# CM33 register map
Registers are 32-bit, read-write, reset 0x0 unless marked. A register's access mark holds for its fields unless they carry their own. Offsets are from the block's base; [hi:lo] are bit positions; {n}, {i} and the like mark numbered series.

## SCB — System Control Block
Base 0xE000ED00
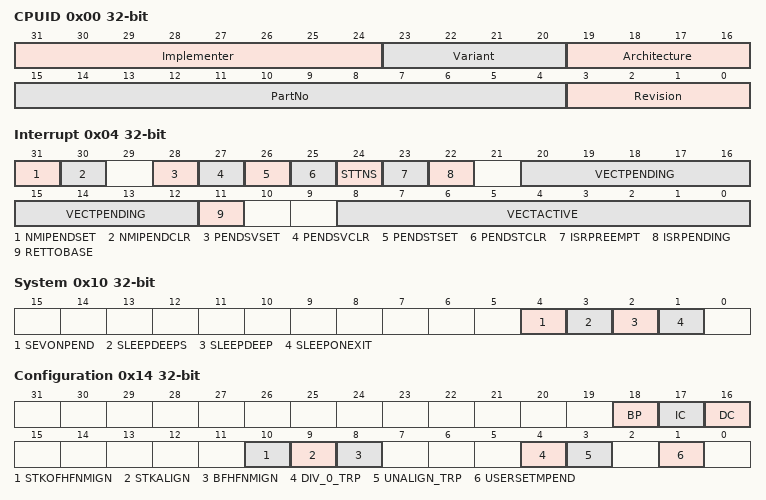
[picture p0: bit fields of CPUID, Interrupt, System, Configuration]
0x00 CPUID Base Register ro — Provides identification information for the PE, including an implementer code for the device and a device ID number
  [31:24] Implementer — Implementer code. This field must hold an implementer code that has been assigned by ARM
  [23:20] Variant — Variant number. IMPLEMENTATION DEFINED variant number
  [19:16] Architecture — Architecture version. Defines the Architecture implemented by the PE
  [15:4] PartNo — Part number. IMPLEMENTATION DEFINED primary part number for the device
  [3:0] Revision — Revision number. IMPLEMENTATION DEFINED revision number for the device
0x04 Interrupt Control and State Register — Controls and provides status information for NMI, PendSV, SysTick and interrupts
  [31] NMIPENDSET write-1-sets — Pend NMI set. Allows the NMI exception to be set as pending
    0=No effect; 1=set pending (Sets the NMI exception pending)
  [30] NMIPENDCLR write-1-sets — Pend NMI clear. Allows the NMI exception pend state to be cleared
    0=No effect; 1=Clear pending status
  [28] PENDSVSET write-1-sets — Pend PendSV set. Indicates whether the PendSV for the selected Security state exception is pending
    0=PendSV exception not pending; 1=set pending (PendSV exception pending)
  [27] PENDSVCLR write-1-sets — Pend PendSV clear
    0=No effect; 1=Clear pending status
  [26] PENDSTSET write-1-sets — Pend SysTick set. Indicates whether the SysTick for the selected Security state exception is pending
    0=cleared (SysTick exception not pending); 1=set_pending (SysTick exception pending)
  [25] PENDSTCLR write-1-sets — Pend SysTick clear
    0=No effect; 1=Clear pending status
  [24] STTNS — SysTick Targets Non-secure
    0=SysTick is Secure; 1=SysTick is Non-secure
  [23] ISRPREEMPT — Interrupt preempt
    0=Will not service; 1=Will service a pending exception
  [22] ISRPENDING — Interrupt pending. Indicates whether an external interrupt, generated by the NVIC, is pending
    0=No external interrupt pending; 1=External interrupt pending
  [20:12] VECTPENDING — Vector pending. The exception number of the highest priority pending and enabled interrupt
  [11] RETTOBASE — Return to base. In Handler mode, indicates whether there is more than one active exception
    0=There is more than one active exception; 1=There is only one active exception
  [8:0] VECTACTIVE — Vector active. The exception number of the current executing exception
0x08 Vector Table Offset Register — Holds the vector table address for the selected Security state
  [31:7] TBLOFF — Bits[31:7] of the vector table address
0x0C Application Interrupt and Reset Control Register — Sets or returns interrupt control and reset configuration
  [31:16] VECTKEY wo range 0x05FA..0x05FA — Vector key. Writes to the AIRCR must be accompanied by a write of the value 0x05FA to this field
    0=Do not request a reset; 0x5FA=Request reset
  [31:16] VECTKEYSTAT ro — Vector key status. Returns the bitwise inverse of the value required to be written to VECTKEY
  [15] ENDIANNESS — Data endianness. Indicates how the PE interprets the memory system data endianness
    0=Little-endian; 1=Big-endian
  [14] PRIS — Prioritize Secure exceptions
    0=Priority ranges of Secure and Non-secure exceptions are identical; 1=Non-secure exceptions are de-prioritized
  [13] BFHFNMINS — BusFault, HardFault, and NMI Non-secure enable
    0=BusFault, HardFault, and NMI are Secure; 1=BusFault and NMI are Non-secure and exceptions can target Non-secure HardFault
  [10:8] PRIGROUP — Priority grouping
    0=Group priority [7:1], subpriority [0]; {v}=Group priority [7:{v+1}], subpriority [{v}:0] (v=1..5)
  [3] SYSRESETREQS — System reset request Secure only
    0=SYSRESETREQ functionality is available to both Security states; 1=SYSRESETREQ functionality is only available to Secure state
  [2] SYSRESETREQ — System reset request. This bit allows software or a debugger to request a system reset
    0=Do not request a system reset; 1=Request reset (Request a system reset)
  [1] VECTCLRACTIVE — Clear active state
    0=Do not clear active state; 1=Clear active state
0x10 System Control Register — Sets or returns system control data
  [4] SEVONPEND — Send event on pend
    0=Transitions from inactive to pending are not wakeup events; 1=Transitions from inactive to pending are wakeup events
  [3] SLEEPDEEPS — Sleep deep secure
    0=The SLEEPDEEP bit accessible from both Security states; 1=The SLEEPDEEP bit behaves as RAZ/WI when accessed from the Non-secure state
  [2] SLEEPDEEP — Sleep deep. Provides a qualifying hint indicating that waking from sleep might take longer
    0=Selected sleep state is not deep sleep; 1=Selected sleep state is deep sleep
  [1] SLEEPONEXIT
    0=Enter sleep state disabled; 1=Enter sleep state permitted
0x14 Configuration and Control Register — Sets or returns configuration and control data
  [18] BP — Branch prediction enable. Enables program flow prediction for the selected Security state
    0=Program flow prediction disabled for the selected Security state; 1=Program flow prediction enabled for the selected Security state
  [17] IC — Instruction cache enable. This is a global enable bit for instruction caches in the selected Security state.
    0=Instruction caches disabled for the selected Security state; 1=Instruction caches enabled for the selected Security state
  [16] DC — Data cache enable. Enables data caching of all data accesses to Normal memory for the selected security state
    0=Data caching disabled for the selected Security state; 1=Data caching enabled for the selected Security state
  [10] STKOFHFNMIGN — Stack overflow in HardFault and NMI ignore. Controls the effect of a stack limit violation while executing at a requested priority less than 0 for the Security state with which the stack limit register is associated
    0=Stack limit faults not ignored; 1=Stack limit faults at requested priorities of less than 0 ignored
  [9] STKALIGN — Stack alignment. Controls whether the stack is automatically aligned to 8-byte boundary on exception entry
    0=Stack aligned to 4-byte boundary on exception entry; 1=Stack automatically aligned to 8-byte boundary on exception entry
  [8] BFHFNMIGN — BusFault in HardFault or NMI ignore. Determines the effect of precise BusFaults on handlers running at a requested priority less than 0
    0=Precise BusFaults not ignored; 1=Precise BusFaults at requested priorities of less than 0 ignored
  [4] DIV_0_TRP — Divide by zero trap. Controls the generation of a DIVBYZERO UsageFault when attempting to perform integer division by zero
    0=DIVBYZERO UsageFault generation disabled; 1=DIVBYZERO UsageFault generation enabled
  [3] UNALIGN_TRP — Unaligned trap. Controls the trapping of unaligned word or halfword accesses
    0=Unaligned accesses permitted from LDR, LDRH, STR, and STRH; 1=Any unaligned transaction generates an UNALIGNED UsageFault
  [1] USERSETMPEND — User set main pending. Determines whether unprivileged accesses are permitted to pend interrupts via the STIR
    0=Unprivileged accesses to the STIR generate a fault; 1=Unprivileged accesses to the STIR are permitted
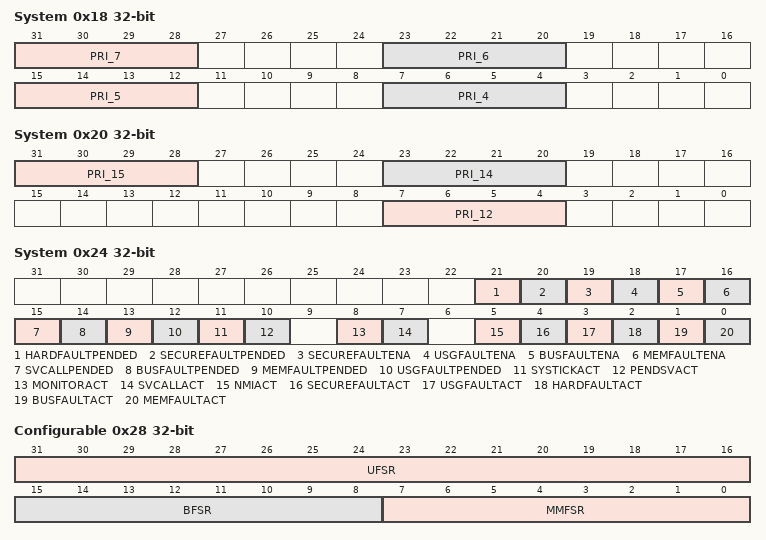
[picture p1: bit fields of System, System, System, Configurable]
0x18 System Handler Priority Register 1 — Sets or returns priority for system handlers 4 - 7
  [31:28] PRI_7 — Priority 7. Priority of system handler 7, SecureFault
  [23:20] PRI_6 — Priority 6. Priority of system handler 6, UsageFault
  [15:12] PRI_5 — Priority 5. Priority of system handler 5, BusFault
  [7:4] PRI_4 — Priority 4. Priority of system handler 4, MemManage
0x1C System Handler Priority Register 2 — Sets or returns priority for system handlers 8 - 11
  [31:28] PRI_11 — Priority 11. Priority of system handler 11, SVCall
0x20 System Handler Priority Register 3 — Sets or returns priority for system handlers 12 - 15
  [31:28] PRI_15 — Priority 15. Priority of system handler 15, SysTick
  [23:20] PRI_14 — Priority 14. Priority of system handler 14, PendSV
  [7:4] PRI_12 — Priority 12. Priority of system handler 12, DebugMonitor
0x24 System Handler Control and State Register — Provides access to the active and pending status of system exceptions
  [21] HARDFAULTPENDED — HardFault exception pended state
    0=HardFault exception not pending for the selected Security state; 1=HardFault exception pending for the selected Security state
  [20] SECUREFAULTPENDED — SecureFault exception pended state
    0=SecureFault exception not pending; 1=SecureFault exception pending
  [19] SECUREFAULTENA — SecureFault exception enable
    0=SecureFault exception disabled; 1=SecureFault exception enabled
  [18] USGFAULTENA — UsageFault exception enable
    0=UsageFault exception disabled for the selected Security state; 1=UsageFault exception enabled for the selected Security state
  [17] BUSFAULTENA — BusFault exception enable. The value of this bit defines whether the BusFault exception is enabled
    0=BusFault exception disabled; 1=BusFault exception enabled
  [16] MEMFAULTENA — MemManage exception enable
    0=MemManage exception disabled for the selected Security state; 1=MemManage exception enabled for the selected Security state
  [15] SVCALLPENDED — SVCall exception pended state
    0=SVCall exception not pending for the selected Security state; 1=SVCall exception pending for the selected Security state
  [14] BUSFAULTPENDED — BusFault exception pended state
    0=BusFault exception not pending; 1=BusFault exception pending
  [13] MEMFAULTPENDED — MemManage exception pended state
    0=MemManage exception not pending for the selected Security state; 1=MemManage exception pending for the selected Security state
  [12] USGFAULTPENDED — UsageFault exception pended state
    0=UsageFault exception not pending for the selected Security state; 1=UsageFault exception pending for the selected Security state
  [11] SYSTICKACT — SysTick exception active state
    0=SysTick exception not active for the selected Security state; 1=SysTick exception active for the selected Security state
  [10] PENDSVACT — PendSV exception active state
    0=PendSV exception not active for the selected Security state; 1=PendSV exception active for the selected Security state
  [8] MONITORACT — DebugMonitor exception active state
    0=DebugMonitor exception not active; 1=DebugMonitor exception active
  [7] SVCALLACT — SVCall exception active state
    0=SVCall exception not active for the selected Security state; 1=SVCall exception active for the selected Security state
  [5] NMIACT — NMI exception active state
    0=NMI exception not active; 1=NMI exception active
  [4] SECUREFAULTACT — SecureFault exception active state
    0=SecureFault exception not active; 1=SecureFault exception active
  [3] USGFAULTACT — UsageFault exception active state for the selected Security state
    0=UsageFault exception not active for the selected Security state; 1=UsageFault exception active for the selected Security state
  [2] HARDFAULTACT — HardFault exception active state
    0=HardFault exception not active for the selected Security state; 1=HardFault exception active for the selected Security state
  [1] BUSFAULTACT — BusFault exception active state
    0=BusFault exception not active; 1=BusFault exception active
  [0] MEMFAULTACT — MemManage exception active state for the selected Security state
    0=MemManage exception not active for the selected Security state; 1=MemManage exception active for the selected Security state
0x28 Configurable Fault Status Register — Contains the three Configurable Fault Status Registers
  [31:16] UFSR — UsageFault Status Register. Provides information on UsageFault exceptions
  [15:8] BFSR — BusFault Status Register. Provides information on BusFault exceptions
  [7:0] MMFSR — MemManage Fault Status Register. Provides information on MemManage exceptions
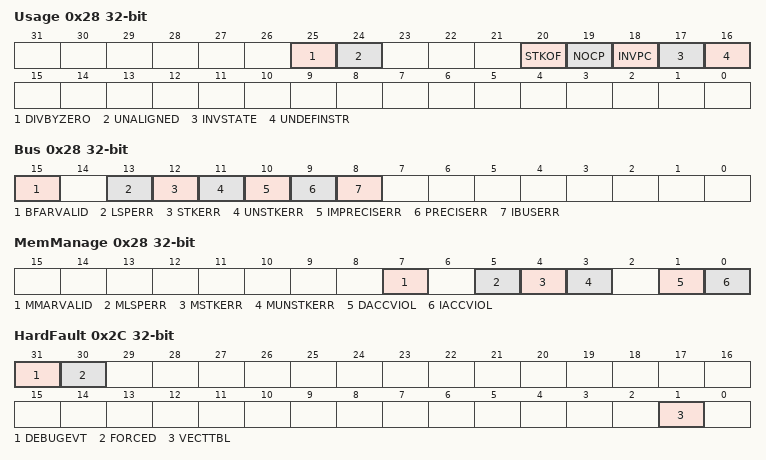
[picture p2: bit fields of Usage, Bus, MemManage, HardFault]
0x28 Usage Fault Status Register — Provides information on UsageFault exceptions
  [all] fields
    0=Error has not occurred; 1=Error has occurred
  [25] DIVBYZERO — Divide by zero flag. Indicates whether an integer division by zero error has occurred
  [24] UNALIGNED — Unaligned access flag. Indicates whether an unaligned access error has occurred
  [20] STKOF — Stack overflow flag. Indicates whether a stack overflow error has occurred
  [19] NOCP — No coprocessor flag. Indicates whether a coprocessor disabled or not present error has occurred
  [18] INVPC — Invalid PC flag. Indicates whether an integrity check error has occurred
  [17] INVSTATE — Invalid state flag. Indicates whether an EPSR.T or EPSR.IT validity error has occurred
  [16] UNDEFINSTR — Undefined instruction flag. Indicates whether an undefined instruction error has occurred
0x28 Bus Fault Status Register — Provides information on BusFault exceptions
  [15] BFARVALID — BFAR valid. Indicates validity of the contents of the BFAR register
    0=BFAR content not valid; 1=BFAR content valid
  [13] LSPERR — Lazy state preservation error. Records whether a BusFault occurred during FP lazy state preservation
    0=No BusFault occurred during FP lazy state preservation; 1=BusFault occurred during FP lazy state preservation
  [12] STKERR — Stack error. Records whether a derived BusFault occurred during exception entry stacking
    0=No derived BusFault occurred; 1=Derived BusFault occurred during exception entry
  [11] UNSTKERR — Unstack error. Records whether a derived BusFault occurred during exception return unstacking
    0=No derived BusFault occurred; 1=Derived BusFault occurred during exception return
  [10] IMPRECISERR — Imprecise error. Records whether an imprecise data access error has occurred
    0=No imprecise data access error has occurred; 1=Imprecise data access error has occurred
  [9] PRECISERR — Precise error. Records whether a precise data access error has occurred
    0=No precise data access error has occurred; 1=Precise data access error has occurred
  [8] IBUSERR — Instruction bus error. Records whether a BusFault on an instruction prefetch has occurred
    0=No BusFault on instruction prefetch has occurred; 1=A BusFault on an instruction prefetch has occurred
0x28 MemManage Fault Status Register — Provides information on MemManage exceptions
  [7] MMARVALID — MMFAR valid flag. Indicates validity of the MMFAR register
    0=MMFAR content not valid; 1=MMFAR content valid
  [5] MLSPERR — MemManage lazy state preservation error flag. Records whether a MemManage fault occurred during FP lazy state preservation
    0=No MemManage occurred during FP lazy state preservation; 1=MemManage occurred during FP lazy state preservation
  [4] MSTKERR — MemManage stacking error flag. Records whether a derived MemManage fault occurred during exception entry stacking
    0=No derived MemManage occurred; 1=Derived MemManage occurred during exception entry
  [3] MUNSTKERR — MemManage unstacking error flag. Records whether a derived MemManage fault occurred during exception return unstacking
    0=No derived MemManage fault occurred; 1=Derived MemManage fault occurred during exception return
  [1] DACCVIOL — Data access violation flag. Records whether a data access violation has occurred
    0=No MemManage fault on data access has occurred; 1=MemManage fault on data access has occurred
  [0] IACCVIOL — Instruction access violation. Records whether an instruction related memory access violation has occurred
    0=No MemManage fault on instruction access has occurred; 1=MemManage fault on instruction access has occurred
0x2C HardFault Status Register — Shows the cause of any HardFaults
  [31] DEBUGEVT — Debug event. Indicates when a debug event has occurred
    0=No debug event has occurred; 1=Debug event has occurred. The Debug Fault Status Register has been updated
  [30] FORCED
    0=No priority escalation has occurred; 1=Processor has escalated a configurable-priority exception to HardFault
  [1] VECTTBL — Vector table
    0=No vector table read fault has occurred
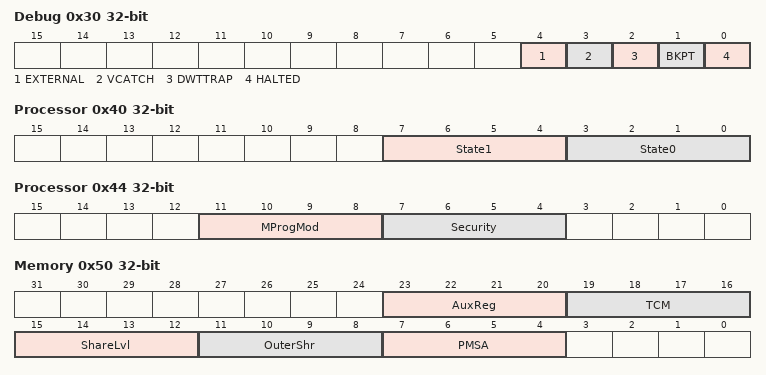
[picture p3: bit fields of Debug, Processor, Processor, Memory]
0x30 Debug Fault Status Register — Shows which debug event occurred
  [all] fields
    0=Debug event has not occurred; 1=Debug event has occurred
  [4] EXTERNAL — External event. Indicates whether an External debug request debug event has occurred
  [3] VCATCH — Vector Catch event. Indicates whether a Vector catch debug event has occurred
  [2] DWTTRAP — Watchpoint event. Indicates whether a Watchpoint debug event has occurred
  [1] BKPT — Breakpoint event. Indicates whether a breakpoint debug event has occurred
  [0] HALTED — Halt or step event
0x34 MemManage Fault Address Register — Shows the address of the memory location that caused an MPU fault
  [31:0] ADDRESS — Data address for an MemManage fault
0x38 BusFault Address Register — Shows the address associated with a precise data access BusFault
  [31:0] ADDRESS — Data address for an BudFault fault
0x3C Auxiliary Fault Status Register — Provides IMPLEMENTATION DEFINED fault status information
  [31:0] IMPLEMENTATION DEFINED — IMPLEMENTATION DEFINED. The contents of this field are IMPLEMENTATION DEFINED
0x40 Processor Feature Register 0 ro — Gives top-level information about the instruction set supported by the PE
  [7:4] State1 — State one. T32 instruction set support
  [3:0] State0 — State two. A32 instruction set support
    0=A32 instruction set not implemented
0x44 Processor Feature Register 1 ro — Gives information about the programmers' model and Extensions support
  [11:8] MProgMod — M programmers' model. Identifies support for the M-Profile programmers' model support
  [7:4] Security — Security. Identifies whether the Security Extension is implemented
    0=Security Extension not implemented; 1=Security Extension implemented
0x48 Debug Feature Register 0 ro — Provides top level information about the debug system
  [23:20] MProfDbg — M-profile debug. Indicates the supported M-profile debug architecture
    0=Halting debug is not implemented; 2=ARMv8-M Debug architecture
0x4C Auxiliary Feature Register 0 ro — Provides information about the IMPLEMENTATION DEFINED features of the PE
  [0] IMPDEFm — IMPLEMENTATION DEFINED. IMPLEMENTATION DEFINED meaning
0x50 Memory Model Feature Register 0 ro — Provides information about the implemented memory model and memory management support
  [23:20] AuxReg — Auxiliary Registers. Indicates support for Auxiliary Control Registers
    0=No Auxiliary Control Registers; 1=Auxiliary Control Registers supported
  [19:16] TCM — Tightly coupled memories. Indicates support for tightly coupled memories (TCMs)
    0=None supported; 1=TCMs supported with IMPLEMENTATION DEFINED control
  [15:12] ShareLvl — Shareability Levels. Indicates the number of shareability levels implemented
    0=One level of shareability implemented; 1=Two levels of shareability implemented
  [11:8] OuterShr — Outermost Shareability. Indicates the outermost shareability domain implemented
    0=Implemented as Non-cacheable; 1=Implemented with hardware coherency support; 15=Shareability ignored
  [7:4] PMSA — Protected memory system architecture
    0=No Supports; 4=Supports PMSAv8
0x58 Memory Model Feature Register 2 ro — Provides information about the implemented memory model and memory management support
  [27:24] WFIStall — WFI stall. Indicates the support for Wait For Interrupt (WFI) stalling
    0=WFI never stalls; 1=WFI has the ability to stall
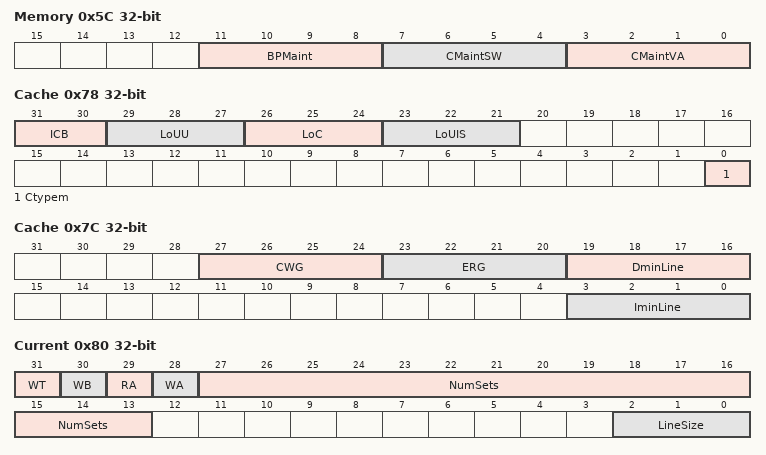
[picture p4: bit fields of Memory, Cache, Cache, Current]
0x5C Memory Model Feature Register 3 ro — Provides information about the implemented memory model and memory management support
  [11:8] BPMaint — Branch predictor maintenance. Indicates the supported branch predictor maintenance
    0=None supported; 1=Support for invalidate all of branch predictors
  [7:4] CMaintSW — Cache maintenance set/way. Indicates the supported cache maintenance operations by set/way
    0=None supported; 1=Maintenance by set/way operations supported
  [3:0] CMaintVA — Cache maintenance by address. Indicates the supported cache maintenance operations by address
    0=None supported; 1=Maintenance by address and instruction cache invalidate all supported
0x78 Cache Level ID Register ro — Identifies the type of caches implemented and the level of coherency and unification
  [31:30] ICB — Inner cache boundary. This field indicates the boundary between inner and outer domain
    0=Not disclosed in this mechanism; 1=L1 cache is the highest inner level; 2=L2 cache is the highest inner level; 3=L3 cache is the highest inner level
  [29:27] LoUU — Level of Unification Uniprocessor
  [26:24] LoC — Level of Coherence. This field indicates the Level of Coherence for the cache hierarchy
  [23:21] LoUIS — Level of Unification Inner Shareable
  [0] Ctypem — Cache type field m. Indicates the type of cache implemented at level m
    0=No cache; 1=Instruction cache only; 2=Data cache only; 3=Separate Instruction And Data Caches; 4=Unified cache
0x7C Cache Type Register ro — Provides information about the architecture of the caches
  [27:24] CWG — Cache Writeback Granule
    0=Indicates that this register does not provide Cache Writeback Granule information and either the architectural maximum of 512 w
  [23:20] ERG — Exclusives Reservation Granule
    0=Indicates that this register does not provide Exclusives Reservation Granule information and the architectural maximum of 512 w
  [19:16] DminLine — Data cache minimum line length
  [3:0] IminLine — Instruction cache minimum line length
0x80 Current Cache Size ID register ro — The CCSIDR provides information about the architecture of the currently selected cache
  [31] WT — Write-Through. Indicates whether the currently selected cache level supports Write-Through
    0=Not supported; 1=Supported
  [30] WB — Writeback. Indicates whether the currently selected cache level supports writeback
    0=Not supported; 1=Supported
  [29] RA — Read-allocate. Indicates whether the currently selected cache level supports read-allocation
    0=Not supported; 1=Supported
  [28] WA — Write-Allocate. Indicates whether the currently selected cache level supports write-allocation
    0=Not supported; 1=Supported
  [27:13] NumSets — Number of sets. Indicates (Number of sets in the currently selected cache) - 1
  [2:0] LineSize — Line size. Indicates (Log2(Number of words per line in the currently selected cache)) - 2
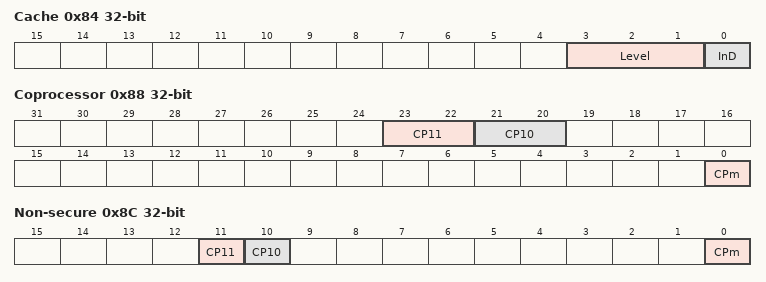
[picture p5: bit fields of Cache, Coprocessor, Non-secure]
0x84 Cache Size Selection Register — Selects the current Cache Size ID Register, CCSIDR, by specifying the required cache level and the cache type (either instruction or data cache)
  [3:1] Level — Cache level. Selects which cache level is to be identified
    {v}=Level {v+1} cache (v=0..6)
  [0] InD — Instruction not data. Selects whether the instruction or the data cache is to be identified
    0=Data or unified cache; 1=Instruction cache
0x88 Coprocessor Access Control Register — Specifies the access privileges for coprocessors and the FP Extension
  [23:22] CP11 — CP11 Privilege. The value in this field is ignored
  [21:20] CP10 — CP10 Privilege. Defines the access rights for the floating-point functionality
    0=All accesses to the FP Extension result in NOCP UsageFault; 1=Unprivileged accesses to the FP Extension result in NOCP UsageFault; 3=Full access to the FP Extension
  [0] CPm — Coprocessor m privilege. Controls access privileges for coprocessor m
    0=Access denied. Any attempted access generates a NOCP UsageFault; 1=Privileged access only. An unprivileged access generates a NOCP UsageFault; 3=Full Access
0x8C Non-secure Access Control Register — Defines the Non-secure access permissions for both the FP Extension and coprocessors CP0 to CP7
  [11] CP11 — CP11 access. Enables Non-secure access to the Floating-point Extension
  [10] CP10 — CP10 access. Enables Non-secure access to the Floating-point Extension
    0=Non-secure accesses to the Floating-point Extension generate a NOCP UsageFault; 1=Non-secure access to the Floating-point Extension permitted
  [0] CPm — CPm access. Enables Non-secure access to coprocessor CPm
    0=Non-secure accesses to this coprocessor generate a NOCP UsageFault; 1=Non-secure access to this coprocessor permitted
